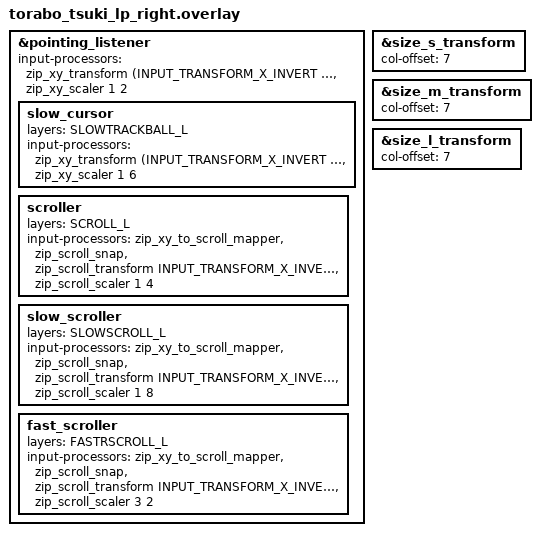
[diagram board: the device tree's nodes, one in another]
#include "torabo_tsuki_lp.dtsi"
#include <input/processors.dtsi>
#include <dt-bindings/zmk/input_transform.h>
#include <scroll-snap.dtsi> // スクロールスナップ ZMK Scroll Snap Module(https://github.com/kot149/zmk-scroll-snap)を使う
#include "../../../config/layers.dtsi"

&pointing_listener {
    input-processors =
        <&zip_xy_transform (INPUT_TRANSFORM_X_INVERT | INPUT_TRANSFORM_Y_INVERT)>,
        <&zip_xy_scaler 1 2>; // カーソル移動速度を遅くする

    // カーソル遅くする
    slow_cursor {
        layers = <SLOWTRACKBALL_L>;
        input-processors =
            <&zip_xy_transform (INPUT_TRANSFORM_X_INVERT | INPUT_TRANSFORM_Y_INVERT)>,
            <&zip_xy_scaler 1 6>;
    };

    scroller {
        layers = <SCROLL_L>;
        input-processors =
            <&zip_xy_to_scroll_mapper>,
            <&zip_scroll_snap>, // スクロールスナップ機能を入れる
            <&zip_scroll_transform INPUT_TRANSFORM_X_INVERT>, // スクロール方向をWindowsに合わせる
            <&zip_scroll_scaler 1 4>; // スクロール速度調整(Soa44では1/8)
    };

    // 低速スクロール（1/8 速度）
    slow_scroller {
        layers = <SLOWSCROLL_L>;
        input-processors =
            <&zip_xy_to_scroll_mapper>,
            <&zip_scroll_snap>, // スクロールスナップ機能を入れる
            <&zip_scroll_transform INPUT_TRANSFORM_X_INVERT>, // スクロール方向をWindowsに合わせる
            <&zip_scroll_scaler 1 8>; // 1/6ではそんなに遅くなかった
    };

    // 高速スクロール
    fast_scroller {
        layers = <FASTRSCROLL_L>;
        input-processors =
            <&zip_xy_to_scroll_mapper>,
            <&zip_scroll_snap>, // スクロールスナップ機能を入れる
            <&zip_scroll_transform INPUT_TRANSFORM_X_INVERT>, // スクロール方向をWindowsに合わせる
            <&zip_scroll_scaler 3 2>; // スクロール速度調整(Soa44では1/8)
    };
};

&size_s_transform {
    col-offset = <7>;
};

&size_m_transform {
    col-offset = <7>;
};

&size_l_transform {
    col-offset = <7>;
};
